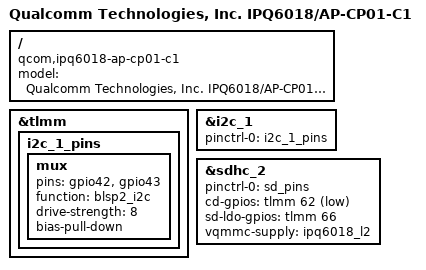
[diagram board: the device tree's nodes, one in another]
// SPDX-License-Identifier: (GPL-2.0+ OR BSD-3-Clause)
/*
 * IPQ6018 CP01 board device tree source
 *
 * Copyright (c) 2019-2021 The Linux Foundation. All rights reserved.
 */

/dts-v1/;

#include "ipq6018-cp01.dtsi"
#include "ipq6018-cpr-regulator.dtsi"

/ {
	model = "Qualcomm Technologies, Inc. IPQ6018/AP-CP01-C1";
	compatible = "qcom,ipq6018-ap-cp01-c1", "qcom,ipq6018-ap-cp01", "qcom,ipq6018";
};

&tlmm {
	i2c_1_pins: i2c_1_pins {
		mux {
			pins = "gpio42", "gpio43";
			function = "blsp2_i2c";
			drive-strength = <8>;
			bias-pull-down;
		};
	};
};

&i2c_1 {
	pinctrl-0 = <&i2c_1_pins>;
	pinctrl-names = "default";
	status = "ok";
};

&sdhc_2 {
	pinctrl-0 = <&sd_pins>;
	pinctrl-names = "default";
	cd-gpios = <&tlmm 62 1>;
	sd-ldo-gpios = <&tlmm 66 0>;
	vqmmc-supply = <&ipq6018_l2>;
	status = "ok";
};
